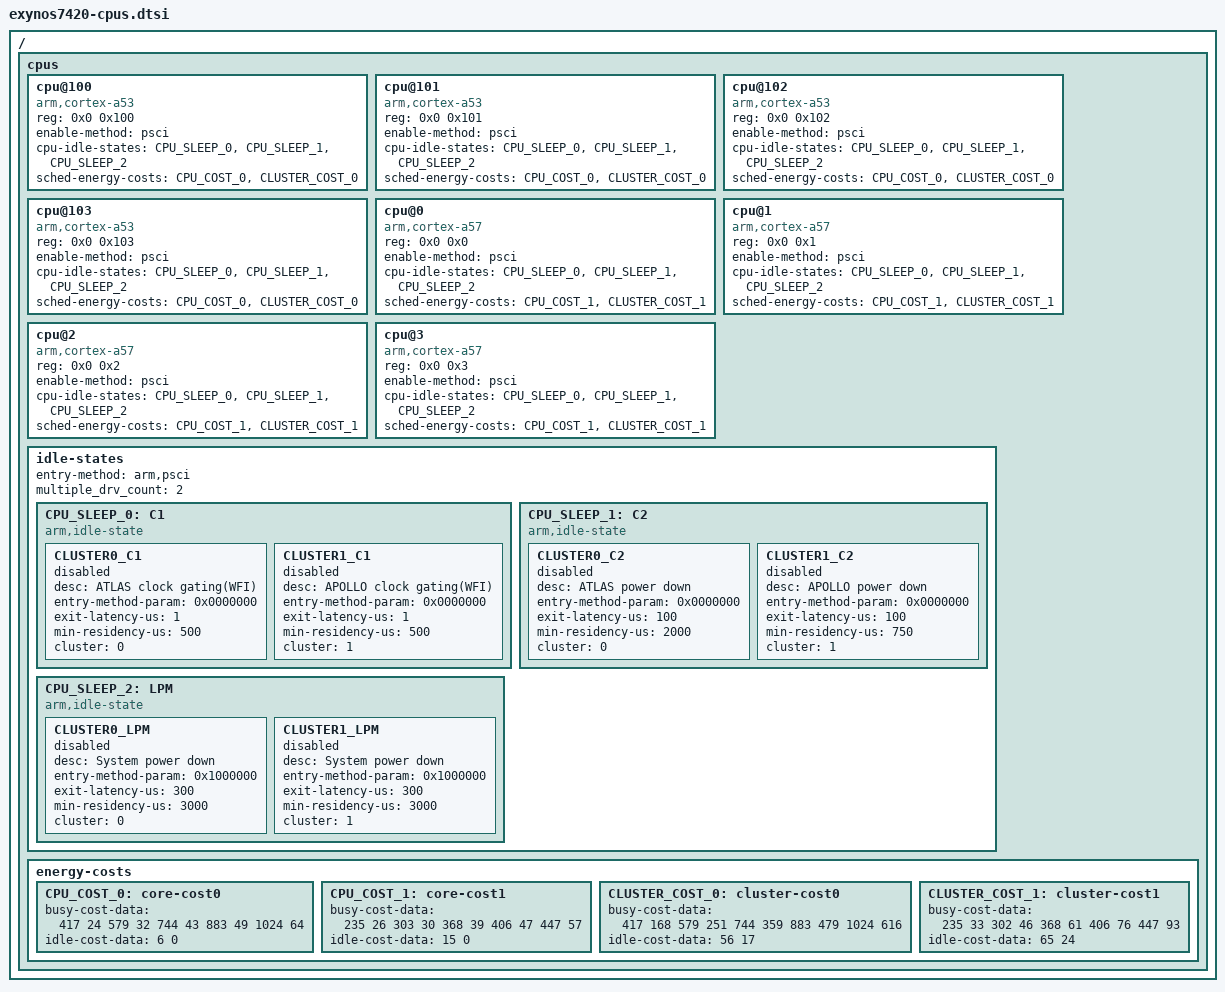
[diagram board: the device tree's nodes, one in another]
/*
 * Energy cost bindings for Energy Aware Scheduling for the Exynos7420 SoC
 *
 * Copyright (c) 2014 Samsung Electronics Co., Ltd.
 *		http://www.samsung.com
 *
 * Copyright (c) 2017 Lukas Berger, TeamNexus <http://github.com/TeamNexus/>
 *
 * This program is free software; you can redistribute it and/or modify
 * it under the terms of the GNU General Public License version 2 as
 * published by the Free Software Foundation.
 */

/ {
	cpus {
		#address-cells = <2>;
		#size-cells = <0>;

		/*
		 * Cluster #0, A53 "Apollo" | Core #1
		 */
		cpu@100 {
			device_type = "cpu";
			compatible = "arm,cortex-a53", "arm,armv8";
			reg = <0x0 0x100>;
			enable-method = "psci";
			cpu-idle-states = <&CPU_SLEEP_0 &CPU_SLEEP_1 &CPU_SLEEP_2>;
			sched-energy-costs = <&CPU_COST_0 &CLUSTER_COST_0>;
		};

		/*
		 * Cluster #0, A53 "APOLLO" | Core #2
		 */
		cpu@101 {
			device_type = "cpu";
			compatible = "arm,cortex-a53", "arm,armv8";
			reg = <0x0 0x101>;
			enable-method = "psci";
			cpu-idle-states = <&CPU_SLEEP_0 &CPU_SLEEP_1 &CPU_SLEEP_2>;
			sched-energy-costs = <&CPU_COST_0 &CLUSTER_COST_0>;
		};

		/*
		 * Cluster #0, A53 "APOLLO" | Core #3
		 */
		cpu@102 {
			device_type = "cpu";
			compatible = "arm,cortex-a53", "arm,armv8";
			reg = <0x0 0x102>;
			enable-method = "psci";
			cpu-idle-states = <&CPU_SLEEP_0 &CPU_SLEEP_1 &CPU_SLEEP_2>;
			sched-energy-costs = <&CPU_COST_0 &CLUSTER_COST_0>;
		};

		/*
		 * Cluster #0, A53 "APOLLO" | Core #4
		 */
		cpu@103 {
			device_type = "cpu";
			compatible = "arm,cortex-a53", "arm,armv8";
			reg = <0x0 0x103>;
			enable-method = "psci";
			cpu-idle-states = <&CPU_SLEEP_0 &CPU_SLEEP_1 &CPU_SLEEP_2>;
			sched-energy-costs = <&CPU_COST_0 &CLUSTER_COST_0>;
		};

		/*
		 * Cluster #1, A57 "ATLAS" | Core #1
		 */
		cpu@0 {
			device_type = "cpu";
			compatible = "arm,cortex-a57", "arm,armv8";
			reg = <0x0 0x0>;
			enable-method = "psci";
			cpu-idle-states = <&CPU_SLEEP_0 &CPU_SLEEP_1 &CPU_SLEEP_2>;
			sched-energy-costs = <&CPU_COST_1 &CLUSTER_COST_1>;
		};

		/*
		 * Cluster #1, A57 "ATLAS" | Core #2
		 */
		cpu@1 {
			device_type = "cpu";
			compatible = "arm,cortex-a57", "arm,armv8";
			reg = <0x0 0x1>;
			enable-method = "psci";
			cpu-idle-states = <&CPU_SLEEP_0 &CPU_SLEEP_1 &CPU_SLEEP_2>;
			sched-energy-costs = <&CPU_COST_1 &CLUSTER_COST_1>;
		};

		/*
		 * Cluster #1, A57 "ATLAS" | Core #3
		 */
		cpu@2 {
			device_type = "cpu";
			compatible = "arm,cortex-a57", "arm,armv8";
			reg = <0x0 0x2>;
			enable-method = "psci";
			cpu-idle-states = <&CPU_SLEEP_0 &CPU_SLEEP_1 &CPU_SLEEP_2>;
			sched-energy-costs = <&CPU_COST_1 &CLUSTER_COST_1>;
		};

		/*
		 * Cluster #1, A57 "ATLAS" | Core #4
		 */
		cpu@3 {
			device_type = "cpu";
			compatible = "arm,cortex-a57", "arm,armv8";
			reg = <0x0 0x3>;
			enable-method = "psci";
			cpu-idle-states = <&CPU_SLEEP_0 &CPU_SLEEP_1 &CPU_SLEEP_2>;
			sched-energy-costs = <&CPU_COST_1 &CLUSTER_COST_1>;
		};

		idle-states {
			entry-method = "arm,psci";
			multiple_drv_count = <2>;

			CPU_SLEEP_0: C1 {
				compatible = "arm,idle-state";

				CLUSTER0_C1 {
					desc = "ATLAS clock gating(WFI)";
					entry-method-param = <0x0000000>;
					exit-latency-us = <1>;
					min-residency-us = <500>;
					status = "enabled";
					cluster = <0>;
				};

				CLUSTER1_C1 {
					desc = "APOLLO clock gating(WFI)";
					entry-method-param = <0x0000000>;
					exit-latency-us = <1>;
					min-residency-us = <500>;
					status = "enabled";
					cluster = <1>;
				};
			};

			CPU_SLEEP_1: C2 {
				compatible = "arm,idle-state";

				CLUSTER0_C2 {
					desc = "ATLAS power down";
					entry-method-param = <0x0000000>;
					exit-latency-us = <100>;
					min-residency-us = <2000>;
					status = "enabled";
					cluster = <0>;
				};

				CLUSTER1_C2 {
					desc = "APOLLO power down";
					entry-method-param = <0x0000000>;
					exit-latency-us = <100>;
					min-residency-us = <750>;
					status = "enabled";
					cluster = <1>;
				};
			};

			CPU_SLEEP_2: LPM {
				compatible = "arm,idle-state";

				CLUSTER0_LPM {
					desc = "System power down";
					entry-method-param = <0x1000000>;
					exit-latency-us = <300>;
					min-residency-us = <3000>;
					status = "enabled";
					cluster = <0>;
				};

				CLUSTER1_LPM {
					desc = "System power down";
					entry-method-param = <0x1000000>;
					exit-latency-us = <300>;
					min-residency-us = <3000>;
					status = "enabled";
					cluster = <1>;
				};
			};
		};

		/*
		 * Based on values taken from
		 * http://www.anandtech.com/show/9330/exynos-7420-deep-dive/5
		 * (P-states got normalized to 1024)
		 */
		energy-costs {
			CPU_COST_0: core-cost0 {
				busy-cost-data = <
					417   24
					579   32
					744   43
					883   49
					1024  64
				>;
				idle-cost-data = <
					6
					0
				>;
			};
			CPU_COST_1: core-cost1 {
				busy-cost-data = <
					235 26
					303 30
					368 39
					406 47
					447 57
				>;
				idle-cost-data = <
					15
					0
				>;
			};
			CLUSTER_COST_0: cluster-cost0 {
				busy-cost-data = <
					417   168
					579   251
					744   359
					883   479
					1024  616
				>;
				idle-cost-data = <
					56
					17
				>;
			};
			CLUSTER_COST_1: cluster-cost1 {
				busy-cost-data = <
					235 33
					302 46
					368 61
					406 76
					447 93
				>;
				idle-cost-data = <
					65
					24
				>;
			};
		};
	};
};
